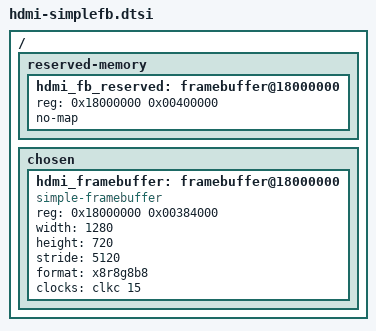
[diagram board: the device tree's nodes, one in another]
/* Include AFTER the generated board/PS DTS. Zynq-7000: one address/size cell.
 * This is a firmware-initialized display: FSBL has already started VDMA.
 * Do not also bind the Linux xilinx-vdma driver to the scanout engine.
 */
/ {
    reserved-memory {
        #address-cells = <1>;
        #size-cells = <1>;
        ranges;
        hdmi_fb_reserved: framebuffer@18000000 {
            reg = <0x18000000 0x00400000>;
            no-map;
        };
    };
    chosen {
        #address-cells = <1>;
        #size-cells = <1>;
        ranges;
        hdmi_framebuffer: framebuffer@18000000 {
            compatible = "simple-framebuffer";
            reg = <0x18000000 0x00384000>;
            width = <1280>;
            height = <720>;
            stride = <5120>;
            format = "x8r8g8b8";
            /* FCLK0 feeds VDMA AXI and HP0; the video MMCM uses K17. keep it enabled. */
            clocks = <&clkc 15>;
            status = "okay";
        };
    };
};
/* If the generated PL DTS contains a VDMA node at 0x43000000, set its
 * status = "disabled" there (or override its actual generated label here).
 * The label varies with device-tree generator version, so no guessed
 * &axi_vdma_0 reference is included in this portable fragment.
 */
